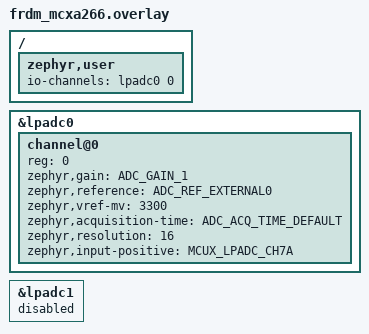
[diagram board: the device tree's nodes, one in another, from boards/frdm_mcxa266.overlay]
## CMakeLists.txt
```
# Copyright 2026 NXP
# SPDX-License-Identifier: Apache-2.0

cmake_minimum_required(VERSION 3.20.0)

# Pulls in this repository as a Zephyr module, which is what makes lib/pm_test,
# include/pm_test and the snippets/pm-* snippets available. Nothing has to be
# passed on the command line: `-S pm-<layer>` is the whole interface.
list(APPEND EXTRA_ZEPHYR_MODULES ${CMAKE_CURRENT_LIST_DIR}/../..)

find_package(Zephyr REQUIRED HINTS $ENV{ZEPHYR_BASE})
project(lpadc_device_pm)

# The suite, the shared LPADC plumbing, and the control test that every layer runs.
target_sources(app PRIVATE src/main.c src/lpadc.c src/test_control.c)

# One file per layer. A layer's file is the only place that layer's claims live,
# so a build for a layer contains no code belonging to any other.
target_sources_ifdef(CONFIG_PM_TEST_LAYER_DEVICE     app PRIVATE src/test_device.c)
target_sources_ifdef(CONFIG_PM_TEST_LAYER_RUNTIME    app PRIVATE src/test_runtime.c)
target_sources_ifdef(CONFIG_PM_TEST_LAYER_SYSTEM     app PRIVATE src/test_system.c)
target_sources_ifdef(CONFIG_PM_TEST_LAYER_SYSMANAGED app PRIVATE src/test_lowpower.c)
target_sources_ifdef(CONFIG_PM_TEST_LAYER_DPD        app PRIVATE src/test_lowpower.c)
```

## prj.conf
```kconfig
# Copyright 2026 NXP
# SPDX-License-Identifier: Apache-2.0
#
# Layer-independent configuration only. The PM symbols come from the layer, which
# comes from the pm-* snippet; see lib/pm_test/Kconfig and docs/pm-layers.md.

CONFIG_ZTEST=y
CONFIG_PM_TEST=y

CONFIG_ADC=y
CONFIG_REGULATOR=y

# Driver logging at info level, immediate: the run ends with interrupts locked so
# that the core cannot park in WFI, and a deferred log would never be flushed.
# include/pm_test/layer.h asserts this pairing.
CONFIG_LOG=y
CONFIG_LOG_MODE_IMMEDIATE=y
CONFIG_ADC_LOG_LEVEL_INF=y
```

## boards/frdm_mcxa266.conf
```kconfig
# Required on this part: without offset calibration the LPADC returns a
# meaningless code. Mirrors samples/drivers/adc/adc_dt/boards/<board>.conf.
CONFIG_LPADC_DO_OFFSET_CALIBRATION=y
```

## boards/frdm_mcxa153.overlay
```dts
/*
 * Copyright 2026 NXP
 * SPDX-License-Identifier: Apache-2.0
 *
 * LPADC channel setup for the device-PM test on FRDM-MCXA153.
 *
 * MCXA has no on-chip Vref regulator node, so the reference is the external
 * VREFH pin (VDD, 3.3 V) and the channel is the one the board already pinmuxes:
 * CH0A (J4 pin 8). Absolute accuracy is not what this test checks -- only that a
 * conversion succeeds vs. fails across PM transitions -- so no wiring is needed.
 *
 * The board dts already sets &lpadc0 to "okay" and applies pinmux_lpadc0.
 */

#include <zephyr/dt-bindings/adc/adc.h>
#include <zephyr/dt-bindings/adc/mcux-lpadc.h>

/ {
	zephyr,user {
		io-channels = <&lpadc0 0>;
	};
};

&lpadc0 {
	#address-cells = <1>;
	#size-cells = <0>;

	channel@0 {
		reg = <0>;
		zephyr,gain = "ADC_GAIN_1";
		zephyr,reference = "ADC_REF_EXTERNAL0";
		zephyr,vref-mv = <3300>;
		zephyr,acquisition-time = <ADC_ACQ_TIME_DEFAULT>;
		zephyr,resolution = <16>;
		zephyr,input-positive = <MCUX_LPADC_CH0A>;
	};
};
```

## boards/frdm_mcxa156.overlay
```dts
/*
 * Copyright 2026 NXP
 * SPDX-License-Identifier: Apache-2.0
 *
 * LPADC channel setup for the device-PM test on FRDM-MCXA156.
 *
 * MCXA has no on-chip Vref regulator node, so the reference is the external
 * VREFH pin (VDD, 3.3 V) and the channel is the one the board already pinmuxes:
 * CH0A (J4 pin 8). Absolute accuracy is not what this test checks -- only that a
 * conversion succeeds vs. fails across PM transitions -- so no wiring is needed.
 *
 * The board dts already sets &lpadc0 to "okay" and applies pinmux_lpadc0.
 */

#include <zephyr/dt-bindings/adc/adc.h>
#include <zephyr/dt-bindings/adc/mcux-lpadc.h>

/ {
	zephyr,user {
		io-channels = <&lpadc0 0>;
	};
};

&lpadc0 {
	#address-cells = <1>;
	#size-cells = <0>;

	channel@0 {
		reg = <0>;
		zephyr,gain = "ADC_GAIN_1";
		zephyr,reference = "ADC_REF_EXTERNAL0";
		zephyr,vref-mv = <3300>;
		zephyr,acquisition-time = <ADC_ACQ_TIME_DEFAULT>;
		zephyr,resolution = <16>;
		zephyr,input-positive = <MCUX_LPADC_CH0A>;
	};
};
```

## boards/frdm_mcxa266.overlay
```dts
/*
 * Copyright 2026 NXP
 * SPDX-License-Identifier: Apache-2.0
 *
 * LPADC channel setup for the device-PM test on FRDM-MCXA266.
 *
 * MCXA has no on-chip Vref regulator node, so the reference is the external
 * VREFH pin (VDD, 3.3 V) and the channel is the one the board already pinmuxes:
 * CH7A (J4 pin 6). Absolute accuracy is not what this test checks -- only that a
 * conversion succeeds vs. fails across PM transitions -- so no wiring is needed.
 *
 * The board dts already sets &lpadc0 to "okay" and applies pinmux_lpadc0.
 */

#include <zephyr/dt-bindings/adc/adc.h>
#include <zephyr/dt-bindings/adc/mcux-lpadc.h>

/ {
	zephyr,user {
		io-channels = <&lpadc0 0>;
	};
};

&lpadc0 {
	#address-cells = <1>;
	#size-cells = <0>;

	channel@0 {
		reg = <0>;
		zephyr,gain = "ADC_GAIN_1";
		zephyr,reference = "ADC_REF_EXTERNAL0";
		zephyr,vref-mv = <3300>;
		zephyr,acquisition-time = <ADC_ACQ_TIME_DEFAULT>;
		zephyr,resolution = <16>;
		zephyr,input-positive = <MCUX_LPADC_CH7A>;
	};
};

/*
 * WORKAROUND for a driver defect, not a test requirement.
 *
 * boards/nxp/frdm_mcxaxx6/board_common.dtsi enables both lpadc0 and lpadc1, and
 * drivers/adc/adc_mcux_lpadc.c cannot be built with CONFIG_PM_DEVICE=y when more than
 * one instance is enabled:
 *
 *   #define LPADC_PM_DEVICE_DEFINE  PM_DEVICE_DT_INST_DEFINE(n, mcux_lpadc_pm_callback);
 *
 * is an object-like macro, so the 'n' in its replacement list is a literal 'n', not the
 * parameter of the LPADC_MCUX_INIT(n) macro it expands inside (parameter substitution
 * happens before nested expansion). Every instance therefore defines the same symbol
 * __pm_device_dts_ord_DT_N_INST_n_nxp_lpc_lpadc_ORD and the second one is a
 * redefinition error. LPADC_PM_DEVICE_GET has the same bug, which is why the
 * single-instance case still links.
 *
 * The fix is to parameterize both macros, e.g. LPADC_PM_DEVICE_DEFINE(n). Until then,
 * disable the instance this test does not drive so the PM phases can actually run.
 */
&lpadc1 {
	status = "disabled";
};
```

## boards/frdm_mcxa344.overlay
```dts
/*
 * Copyright 2026 NXP
 * SPDX-License-Identifier: Apache-2.0
 *
 * LPADC channel setup for the device-PM test on FRDM-MCXA344.
 *
 * MCXA has no on-chip Vref regulator node, so the reference is the external
 * VREFH pin (VDD, 3.3 V) and the channel is the one the board already pinmuxes:
 * CH7A (J2 pin 1). Absolute accuracy is not what this test checks -- only that a
 * conversion succeeds vs. fails across PM transitions -- so no wiring is needed.
 *
 * The board dts already sets &lpadc0 to "okay" and applies pinmux_lpadc0.
 */

#include <zephyr/dt-bindings/adc/adc.h>
#include <zephyr/dt-bindings/adc/mcux-lpadc.h>

/ {
	zephyr,user {
		io-channels = <&lpadc0 0>;
	};
};

&lpadc0 {
	#address-cells = <1>;
	#size-cells = <0>;

	channel@0 {
		reg = <0>;
		zephyr,gain = "ADC_GAIN_1";
		zephyr,reference = "ADC_REF_EXTERNAL0";
		zephyr,vref-mv = <3300>;
		zephyr,acquisition-time = <ADC_ACQ_TIME_DEFAULT>;
		zephyr,resolution = <16>;
		zephyr,input-positive = <MCUX_LPADC_CH7A>;
	};
};
```

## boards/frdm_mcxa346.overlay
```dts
/*
 * Copyright 2026 NXP
 * SPDX-License-Identifier: Apache-2.0
 *
 * LPADC channel setup for the device-PM test on FRDM-MCXA346.
 *
 * MCXA has no on-chip Vref regulator node, so the reference is the external
 * VREFH pin (VDD, 3.3 V) and the channel is the one the board already pinmuxes:
 * CH7A (J4 pin 6). Absolute accuracy is not what this test checks -- only that a
 * conversion succeeds vs. fails across PM transitions -- so no wiring is needed.
 *
 * The board dts already sets &lpadc0 to "okay" and applies pinmux_lpadc0.
 */

#include <zephyr/dt-bindings/adc/adc.h>
#include <zephyr/dt-bindings/adc/mcux-lpadc.h>

/ {
	zephyr,user {
		io-channels = <&lpadc0 0>;
	};
};

&lpadc0 {
	#address-cells = <1>;
	#size-cells = <0>;

	channel@0 {
		reg = <0>;
		zephyr,gain = "ADC_GAIN_1";
		zephyr,reference = "ADC_REF_EXTERNAL0";
		zephyr,vref-mv = <3300>;
		zephyr,acquisition-time = <ADC_ACQ_TIME_DEFAULT>;
		zephyr,resolution = <16>;
		zephyr,input-positive = <MCUX_LPADC_CH7A>;
	};
};

/*
 * WORKAROUND for a driver defect, not a test requirement.
 *
 * boards/nxp/frdm_mcxaxx6/board_common.dtsi enables both lpadc0 and lpadc1, and
 * drivers/adc/adc_mcux_lpadc.c cannot be built with CONFIG_PM_DEVICE=y when more than
 * one instance is enabled:
 *
 *   #define LPADC_PM_DEVICE_DEFINE  PM_DEVICE_DT_INST_DEFINE(n, mcux_lpadc_pm_callback);
 *
 * is an object-like macro, so the 'n' in its replacement list is a literal 'n', not the
 * parameter of the LPADC_MCUX_INIT(n) macro it expands inside (parameter substitution
 * happens before nested expansion). Every instance therefore defines the same symbol
 * __pm_device_dts_ord_DT_N_INST_n_nxp_lpc_lpadc_ORD and the second one is a
 * redefinition error. LPADC_PM_DEVICE_GET has the same bug, which is why the
 * single-instance case still links.
 *
 * The fix is to parameterize both macros, e.g. LPADC_PM_DEVICE_DEFINE(n). Until then,
 * disable the instance this test does not drive so the PM phases can actually run.
 */
&lpadc1 {
	status = "disabled";
};
```

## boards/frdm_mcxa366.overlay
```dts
/*
 * Copyright 2026 NXP
 * SPDX-License-Identifier: Apache-2.0
 *
 * LPADC channel setup for the device-PM test on FRDM-MCXA366.
 *
 * MCXA has no on-chip Vref regulator node, so the reference is the external
 * VREFH pin (VDD, 3.3 V) and the channel is the one the board already pinmuxes:
 * CH7A (J4 pin 6). Absolute accuracy is not what this test checks -- only that a
 * conversion succeeds vs. fails across PM transitions -- so no wiring is needed.
 *
 * The board dts already sets &lpadc0 to "okay" and applies pinmux_lpadc0.
 */

#include <zephyr/dt-bindings/adc/adc.h>
#include <zephyr/dt-bindings/adc/mcux-lpadc.h>

/ {
	zephyr,user {
		io-channels = <&lpadc0 0>;
	};
};

&lpadc0 {
	#address-cells = <1>;
	#size-cells = <0>;

	channel@0 {
		reg = <0>;
		zephyr,gain = "ADC_GAIN_1";
		zephyr,reference = "ADC_REF_EXTERNAL0";
		zephyr,vref-mv = <3300>;
		zephyr,acquisition-time = <ADC_ACQ_TIME_DEFAULT>;
		zephyr,resolution = <16>;
		zephyr,input-positive = <MCUX_LPADC_CH7A>;
	};
};

/*
 * WORKAROUND for a driver defect, not a test requirement.
 *
 * boards/nxp/frdm_mcxaxx6/board_common.dtsi enables both lpadc0 and lpadc1, and
 * drivers/adc/adc_mcux_lpadc.c cannot be built with CONFIG_PM_DEVICE=y when more than
 * one instance is enabled:
 *
 *   #define LPADC_PM_DEVICE_DEFINE  PM_DEVICE_DT_INST_DEFINE(n, mcux_lpadc_pm_callback);
 *
 * is an object-like macro, so the 'n' in its replacement list is a literal 'n', not the
 * parameter of the LPADC_MCUX_INIT(n) macro it expands inside (parameter substitution
 * happens before nested expansion). Every instance therefore defines the same symbol
 * __pm_device_dts_ord_DT_N_INST_n_nxp_lpc_lpadc_ORD and the second one is a
 * redefinition error. LPADC_PM_DEVICE_GET has the same bug, which is why the
 * single-instance case still links.
 *
 * The fix is to parameterize both macros, e.g. LPADC_PM_DEVICE_DEFINE(n). Until then,
 * disable the instance this test does not drive so the PM phases can actually run.
 */
&lpadc1 {
	status = "disabled";
};
```

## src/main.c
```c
/*
 * Copyright 2026 NXP
 * SPDX-License-Identifier: Apache-2.0
 */

/**
 * @file
 * @brief LPADC device-PM suite: the suite hooks, and nothing else.
 *
 * Which layer this build tests, and therefore which src/test_*.c is compiled in,
 * is decided by the pm-* snippet on the command line. See docs/pm-layers.md.
 */

#include <zephyr/ztest.h>

#include <pm_test/layer.h>

#include "lpadc.h"

/*
 * Channel setup happens once, in setup(), rather than before every test: the
 * reference supplies a channel setup touches are use-counted, and repeating it
 * would be testing that rather than the layer.
 */
static int setup_rc = -EBUSY;

static void *lpadc_pm_setup(void)
{
	(void)pm_test_setup();
	setup_rc = lpadc_channels_setup();
	return NULL;
}

static void lpadc_pm_before(void *fixture)
{
	ARG_UNUSED(fixture);

	/* Reported from before() because a setup() that fails has no way to fail
	 * the suite -- this way every test in the run says why it is meaningless.
	 */
	zassert_ok(setup_rc, "LPADC channel setup failed (%d)", setup_rc);
}

ZTEST_SUITE(lpadc_pm, NULL, lpadc_pm_setup, lpadc_pm_before, NULL, NULL);
```

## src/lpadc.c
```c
/*
 * Copyright 2026 NXP
 * SPDX-License-Identifier: Apache-2.0
 */

/**
 * @file
 * @brief The LPADC itself: the wiring, and the one observation this case makes.
 */

#include <zephyr/devicetree.h>
#include <zephyr/sys/util.h>

#include "lpadc.h"

#if !DT_NODE_EXISTS(DT_PATH(zephyr_user)) ||                                                       \
	!DT_NODE_HAS_PROP(DT_PATH(zephyr_user), io_channels)
#error "This board has no LPADC wiring: add boards/<board_target>.overlay with zephyr,user io-channels"
#endif

#define DT_SPEC_AND_COMMA_FOR_INPUTS(node_id, prop, idx)                                           \
	COND_CODE_1(DT_PHA_HAS_CELL_AT_IDX(node_id, prop, idx, input),                              \
		    (ADC_DT_SPEC_GET_BY_IDX(node_id, idx),), ())

const struct adc_dt_spec lpadc_channels[] = {
	DT_FOREACH_PROP_ELEM(DT_PATH(zephyr_user), io_channels, DT_SPEC_AND_COMMA_FOR_INPUTS)
};

int lpadc_channels_setup(void)
{
	for (size_t i = 0U; i < ARRAY_SIZE(lpadc_channels); i++) {
		int err;

		if (!adc_is_ready_dt(&lpadc_channels[i])) {
			return -ENODEV;
		}

		err = adc_channel_setup_dt(&lpadc_channels[i]);
		if (err < 0) {
			return err;
		}
	}

	return 0;
}

int lpadc_read(int32_t *out_raw)
{
	int16_t buf;
	struct adc_sequence sequence = {
		.buffer = &buf,
		.buffer_size = sizeof(buf),
	};
	int err;

	err = adc_sequence_init_dt(&lpadc_channels[0], &sequence);
	if (err < 0) {
		return err;
	}

	err = adc_read_dt(&lpadc_channels[0], &sequence);
	if (err < 0) {
		return err;
	}

	*out_raw = buf;
	return 0;
}
```

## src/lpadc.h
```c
/*
 * Copyright 2026 NXP
 * SPDX-License-Identifier: Apache-2.0
 */

/**
 * @file
 * @brief What every layer of the LPADC case needs from the hardware.
 *
 * The one observable this case has is whether a conversion completes. The
 * driver's SUSPEND action calls LPADC_Enable(false), so "a read works" and "the
 * block is powered and configured" are the same question -- which is what lets
 * every layer be tested through this single operation.
 */

#ifndef LPADC_PM_H_
#define LPADC_PM_H_

#include <stdint.h>
#include <zephyr/drivers/adc.h>

/** The channels named by zephyr,user io-channels in the board overlay. */
extern const struct adc_dt_spec lpadc_channels[];

/** The LPADC controller itself: the parent of those channels. */
#define LPADC_DEV (lpadc_channels[0].dev)

/**
 * @brief Configure every channel this board wired up.
 *
 * Also exercised as a test in its own right by the runtime layer, which calls it
 * against a suspended device.
 *
 * @return 0 on success, negative errno from adc_channel_setup_dt() otherwise.
 */
int lpadc_channels_setup(void);

/**
 * @brief Perform one conversion on channel 0.
 *
 * @param out_raw where to store the raw sample; untouched on failure.
 *
 * @return 0 on a completed conversion, negative errno otherwise.
 */
int lpadc_read(int32_t *out_raw);

#endif /* LPADC_PM_H_ */
```

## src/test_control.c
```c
/*
 * Copyright 2026 NXP
 * SPDX-License-Identifier: Apache-2.0
 */

/**
 * @file
 * @brief The control: this case really does drive the peripheral.
 *
 * Compiled into every layer, not just the baseline one. If this fails, no verdict
 * from the layer under test means anything -- which is the whole reason the
 * baseline layer exists as a layer.
 */

#include <zephyr/ztest.h>
#include <zephyr/pm/device_runtime.h>

#include "lpadc.h"

ZTEST(lpadc_pm, test_control_read)
{
	int32_t raw = 0;
	bool held = false;
	int rc;

	/*
	 * Where runtime PM owns the device it boots suspended, so the control has
	 * to ask for it explicitly. Reading without a reference is a claim about
	 * the driver -- that its read path holds one for the length of the
	 * sequence -- and test_runtime.c is where that claim is judged. Making the
	 * control depend on it too would mean one driver defect failed every case
	 * in the layer, which is the opposite of what a control is for.
	 */
	if (pm_device_runtime_is_enabled(LPADC_DEV)) {
		zassert_ok(pm_device_runtime_get(LPADC_DEV),
			   "could not resume the device for the control read");
		held = true;
	}

	rc = lpadc_read(&raw);

	if (held) {
		/* Before the assert below: a failed read must not leak the reference. */
		(void)pm_device_runtime_put(LPADC_DEV);
	}

	zassert_ok(rc, "control conversion did not complete");
	TC_PRINT("control raw=%d\n", raw);
}
```

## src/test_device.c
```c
/*
 * Copyright 2026 NXP
 * SPDX-License-Identifier: Apache-2.0
 */

/**
 * @file
 * @brief The device layer: the driver's SUSPEND/RESUME callbacks, driven directly.
 *
 * One test, because the sequence is the claim: a device that is ACTIVE, then
 * suspended, then resumed. Splitting it would leave tests that only pass in the
 * order ztest happens to run them.
 */

#include <zephyr/pm/device.h>
#include <zephyr/ztest.h>

#include <pm_test/state.h>

#include "lpadc.h"

ZTEST(lpadc_pm, test_device_suspend_resume)
{
	int32_t raw = 0;
	int err;

	/* No runtime PM in this layer, so pm_device_driver_init() resumed it. */
	zassert_pm_state(LPADC_DEV, PM_DEVICE_STATE_ACTIVE);

	zassert_ok(pm_device_action_run(LPADC_DEV, PM_DEVICE_ACTION_SUSPEND),
		   "SUSPEND action rejected");
	zassert_pm_state(LPADC_DEV, PM_DEVICE_STATE_SUSPENDED);

	/*
	 * The driver's SUSPEND calls LPADC_Enable(false), so a conversion started
	 * now cannot complete. -EBUSY is the contract: rejecting the request is the
	 * only acceptable behaviour, and returning it is what the driver was fixed
	 * to do -- see lpadc-suspended-read-hangs in docs/findings.md, where it used
	 * to hang instead and took three of the six layers down with it.
	 */
	err = lpadc_read(&raw);
	zassert_equal(err, -EBUSY, "read against a SUSPENDED device returned %d, want -EBUSY", err);

	zassert_ok(pm_device_action_run(LPADC_DEV, PM_DEVICE_ACTION_RESUME),
		   "RESUME action rejected");
	zassert_pm_state(LPADC_DEV, PM_DEVICE_STATE_ACTIVE);

	zassert_ok(lpadc_read(&raw), "conversion did not complete after RESUME");
	TC_PRINT("post-resume raw=%d\n", raw);

	/* A redundant action must be refused, not obeyed and not fatal. */
	err = pm_device_action_run(LPADC_DEV, PM_DEVICE_ACTION_RESUME);
	zassert_equal(err, -EALREADY, "second RESUME returned %d, want -EALREADY", err);
}
```

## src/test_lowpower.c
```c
/*
 * Copyright 2026 NXP
 * SPDX-License-Identifier: Apache-2.0
 */

/**
 * @file
 * @brief The sysmanaged and dpd layers: the device sweep across one transition.
 *
 * One file for two layers, because the sequence is identical and only the state
 * being entered differs -- and that difference is what separates the two claims.
 * In sysmanaged the sweep's SUSPEND and RESUME are all that happen. In dpd the
 * peripheral actually loses power, so a RESUME that only re-enables the block is
 * not enough: the core domain hands the driver TURN_OFF and TURN_ON, and the
 * driver has to reconfigure and recalibrate a register block that came back from
 * reset. dpd is the only layer that can catch a driver with no restore path -- see
 * lpadc-no-restore-after-dpd in docs/findings.md.
 */

#include <zephyr/pm/device.h>
#include <zephyr/ztest.h>

#include <pm_test/lowpower.h>
#include <pm_test/state.h>

#include "lpadc.h"

ZTEST(lpadc_pm, test_sweep_across_transition)
{
	int32_t raw = 0;

	/* No runtime PM in these layers, so the sweep is the only thing that will
	 * suspend the device.
	 */
	zassert_pm_state(LPADC_DEV, PM_DEVICE_STATE_ACTIVE);
	zassert_ok(lpadc_read(&raw), "conversion failed before the transition");

	pm_test_enter_transition();
	pm_test_console_resume(PM_TEST_CONSOLE_REINIT_PINMUX);
	TC_PRINT("resumed from %s\n", PM_TEST_TRANSITION_NAME);

	/*
	 * pm_resume_devices() walks the devices it suspended in init order, so the
	 * core domain's TURN_ON has already run by the time the LPADC's own RESUME
	 * does. The two together have to leave a converter that works.
	 */
	zassert_pm_state(LPADC_DEV, PM_DEVICE_STATE_ACTIVE);
	zassert_ok(lpadc_read(&raw), "conversion failed after the transition");
	TC_PRINT("post-transition raw=%d\n", raw);
}
```

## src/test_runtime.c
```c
/*
 * Copyright 2026 NXP
 * SPDX-License-Identifier: Apache-2.0
 */

/**
 * @file
 * @brief The runtime layer: pm_device_runtime_get()/put() reference counting.
 *
 * Two tests. The first is one ordered sequence because it starts from the state
 * the device booted in, which nothing else may have disturbed. The second stands
 * on its own: it only needs the device suspended, which is true both at boot and
 * after the first test's put().
 */

#include <zephyr/pm/device.h>
#include <zephyr/pm/device_runtime.h>
#include <zephyr/ztest.h>

#include <pm_test/state.h>

#include "lpadc.h"

/*
 * The reference the read path takes is dropped with pm_device_runtime_put_async()
 * from the completion interrupt, so the suspend itself runs later on the system
 * work queue. Let it run before sampling the state.
 */
static void settle_async_suspend(void)
{
	k_msleep(20);
}

ZTEST(lpadc_pm, test_runtime_reference_counting)
{
	int32_t raw = 0;

	/* With runtime PM, pm_device_driver_init() leaves the device SUSPENDED. */
	zassert_pm_state(LPADC_DEV, PM_DEVICE_STATE_SUSPENDED);

	/*
	 * The read path holds a reference for the length of the sequence, so an
	 * unwrapped read resumes the converter, converts, and lets it go again.
	 */
	zassert_ok(lpadc_read(&raw), "unwrapped read did not auto-resume");
	TC_PRINT("unwrapped raw=%d\n", raw);

	settle_async_suspend();
	zassert_pm_state(LPADC_DEV, PM_DEVICE_STATE_SUSPENDED);

	/*
	 * A caller holding its own reference across several reads keeps the
	 * converter up, and the reads must not disturb that reference.
	 */
	zassert_ok(pm_device_runtime_get(LPADC_DEV), "runtime_get rejected");
	zassert_pm_state(LPADC_DEV, PM_DEVICE_STATE_ACTIVE);

	zassert_ok(lpadc_read(&raw), "read under a held reference failed");
	TC_PRINT("wrapped raw=%d\n", raw);

	settle_async_suspend();
	zassert_pm_state(LPADC_DEV, PM_DEVICE_STATE_ACTIVE);

	zassert_ok(pm_device_runtime_put(LPADC_DEV), "runtime_put rejected");
	zassert_pm_state(LPADC_DEV, PM_DEVICE_STATE_SUSPENDED);
}

ZTEST(lpadc_pm, test_runtime_channel_setup_while_suspended)
{
	int32_t raw = 0;

	zassert_pm_state(LPADC_DEV, PM_DEVICE_STATE_SUSPENDED);

	/*
	 * channel_setup() must not touch the reference supplies while the device is
	 * suspended: doing so leaves the regulator's use count high for good -- see
	 * lpadc-channel-setup-unbalances-bandgap in docs/findings.md. All it may do
	 * is record what the next RESUME has to apply.
	 */
	zassert_ok(lpadc_channels_setup(), "channel setup against a SUSPENDED device failed");
	zassert_pm_state(LPADC_DEV, PM_DEVICE_STATE_SUSPENDED);

	/* And what it recorded has to actually be applied on the way back up. */
	zassert_ok(lpadc_read(&raw), "read after a suspended channel setup failed");
	TC_PRINT("post-setup raw=%d\n", raw);

	settle_async_suspend();
}
```

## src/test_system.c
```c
/*
 * Copyright 2026 NXP
 * SPDX-License-Identifier: Apache-2.0
 */

/**
 * @file
 * @brief The system layer: the per-conversion power state constraint.
 *
 * &lpadc0 lists the states that stop it converting in zephyr,disabling-power-states
 * (see constraints.overlay), and the driver takes a pm_policy_device_power_lock
 * around each conversion. Both halves of that pair are observable through the
 * policy API, so both are checked: nothing held before the conversion, and nothing
 * left behind after it. A leaked lock would block those states for the rest of the
 * run, which is invisible until something measures the power.
 */

#include <zephyr/pm/policy.h>
#include <zephyr/ztest.h>

#include <pm_test/lowpower.h>

#include "lpadc.h"

ZTEST(lpadc_pm, test_system_constraint_is_taken_and_released)
{
	int32_t raw = 0;

	pm_test_console_quiesce();
	zassert_false(pm_policy_state_lock_is_active(PM_STATE_SUSPEND_TO_IDLE, PM_ALL_SUBSTATES),
		      "a constraint was already held before the conversion");

	zassert_ok(lpadc_read(&raw), "constrained conversion did not complete");
	TC_PRINT("constrained raw=%d\n", raw);

	pm_test_console_quiesce();
	zassert_false(pm_policy_state_lock_is_active(PM_STATE_SUSPEND_TO_IDLE, PM_ALL_SUBSTATES),
		      "the conversion's constraint was not released");
}
```
